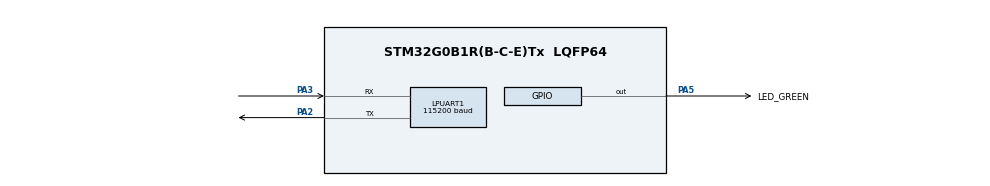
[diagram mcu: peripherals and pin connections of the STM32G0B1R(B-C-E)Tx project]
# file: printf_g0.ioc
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LPUART1.BaudRate=115200
LPUART1.WordLength=UART_WORDLENGTH_8B
Mcu.Family=STM32G0
Mcu.Name=STM32G0B1R(B-C-E)Tx
Mcu.Package=LQFP64
PA13.GPIO_Label=TMS
PA13.Signal=SYS_SWDIO
PA14-BOOT0.GPIO_Label=TCK
PA14-BOOT0.Signal=SYS_SWCLK
PA2.Mode=Asynchronous
PA2.Signal=LPUART1_TX
PA3.Mode=Asynchronous
PA3.Signal=LPUART1_RX
PA5.GPIO_Label=LED_GREEN
PA5.GPIO_Speed=GPIO_SPEED_FREQ_HIGH
PA5.Signal=GPIO_Output
PC13.Signal=SYS_WKUP2
PC14-OSC32_IN\ (PC14).Signal=RCC_OSC32_IN
PC15-OSC32_OUT\ (PC15).Signal=RCC_OSC32_OUT
PF0-OSC_IN\ (PF0).GPIO_Label=MCO
PF0-OSC_IN\ (PF0).Signal=RCC_OSC_IN
ProjectManager.HeapSize=0x200
ProjectManager.StackSize=0x400
ProjectManager.TargetToolchain=STM32CubeIDE
RCC.ADCFreq_Value=64000000
RCC.AHBFreq_Value=64000000
RCC.CortexFreq_Value=64000000
RCC.EXTERNAL_CLOCK_VALUE=12288000
RCC.HCLKFreq_Value=64000000
RCC.HSE_VALUE=8000000
RCC.HSI48_VALUE=48000000
RCC.HSI_VALUE=16000000
RCC.LSE_VALUE=32768
RCC.SYSCLKFreq_VALUE=64000000
RCC.SYSCLKSource=RCC_SYSCLKSOURCE_PLLCLK
RCC.USBFreq_Value=48000000
RCC.VCOOutputFreq_Value=128000000
VP_SYS_VS_DBSignals.Mode=DisableDeadBatterySignals
board=NUCLEO-G0B1RE

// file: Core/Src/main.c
/* USER CODE BEGIN Header */
/**
  ******************************************************************************
  * @file           : main.c
  * @brief          : Main program body
  ******************************************************************************
  * @attention
  *
  * Copyright (c) 2024 STMicroelectronics.
  * All rights reserved.
  *
  * This software is licensed under terms that can be found in the LICENSE file
  * in the root directory of this software component.
  * If no LICENSE file comes with this software, it is provided AS-IS.
  *
  ******************************************************************************
  */
/* USER CODE END Header */
#include "main.h"
#include<stdio.h>

UART_HandleTypeDef hlpuart1;

void SystemClock_Config(void);
static void MX_GPIO_Init(void);
static void MX_LPUART1_UART_Init(void);
/* USER CODE BEGIN PFP */
#define PUTCHAR_PROTOTYPE int fputc(int ch, FILE *f)
/* USER CODE END PFP */

int main(void)
{

  /* MCU Configuration--------------------------------------------------------*/

  /* Reset of all peripherals, Initializes the Flash interface and the Systick. */
  HAL_Init();

  /* Configure the system clock */
  SystemClock_Config();

  /* Initialize all configured peripherals */
  MX_GPIO_Init();
  MX_LPUART1_UART_Init();

  /* Infinite loop */
  while (1)
  {

    /* USER CODE BEGIN 3 */

LL_GPIO_TogglePin(GPIOA, LL_GPIO_PIN_5);
LL_mDelay(1000);
     // printf("** Hello World ** \n\r");
      //HAL_Delay(1000);
  }
  /* USER CODE END 3 */
}

void SystemClock_Config(void)
{
  LL_FLASH_SetLatency(LL_FLASH_LATENCY_2);
  while(LL_FLASH_GetLatency() != LL_FLASH_LATENCY_2)
  {
  }

  /* HSI configuration and activation */
  LL_RCC_HSI_Enable();
  while(LL_RCC_HSI_IsReady() != 1)
  {
  }

  /* Main PLL configuration and activation */
  LL_RCC_PLL_ConfigDomain_SYS(LL_RCC_PLLSOURCE_HSI, LL_RCC_PLLM_DIV_1, 8, LL_RCC_PLLR_DIV_2);
  LL_RCC_PLL_Enable();
  LL_RCC_PLL_EnableDomain_SYS();
  while(LL_RCC_PLL_IsReady() != 1)
  {
  }

  /* Set AHB prescaler*/
  LL_RCC_SetAHBPrescaler(LL_RCC_SYSCLK_DIV_1);

  /* Sysclk activation on the main PLL */
  LL_RCC_SetSysClkSource(LL_RCC_SYS_CLKSOURCE_PLL);
  while(LL_RCC_GetSysClkSource() != LL_RCC_SYS_CLKSOURCE_STATUS_PLL)
  {
  }

  /* Set APB1 prescaler*/
  LL_RCC_SetAPB1Prescaler(LL_RCC_APB1_DIV_1);
  /* Update CMSIS variable (which can be updated also through SystemCoreClockUpdate function) */
  LL_SetSystemCoreClock(64000000);

   /* Update the time base */
  if (HAL_InitTick (TICK_INT_PRIORITY) != HAL_OK)
  {
    Error_Handler();
  }
}

static void MX_LPUART1_UART_Init(void)
{

  hlpuart1.Instance = LPUART1;
  hlpuart1.Init.BaudRate = 115200;
  hlpuart1.Init.WordLength = UART_WORDLENGTH_8B;
  hlpuart1.Init.StopBits = UART_STOPBITS_1;
  hlpuart1.Init.Parity = UART_PARITY_NONE;
  hlpuart1.Init.Mode = UART_MODE_TX_RX;
  hlpuart1.Init.HwFlowCtl = UART_HWCONTROL_NONE;
  hlpuart1.Init.OneBitSampling = UART_ONE_BIT_SAMPLE_DISABLE;
  hlpuart1.Init.ClockPrescaler = UART_PRESCALER_DIV1;
  hlpuart1.AdvancedInit.AdvFeatureInit = UART_ADVFEATURE_NO_INIT;
  hlpuart1.FifoMode = UART_FIFOMODE_DISABLE;
  if (HAL_UART_Init(&hlpuart1) != HAL_OK)
  {
    Error_Handler();
  }
  if (HAL_UARTEx_SetTxFifoThreshold(&hlpuart1, UART_TXFIFO_THRESHOLD_1_8) != HAL_OK)
  {
    Error_Handler();
  }
  if (HAL_UARTEx_SetRxFifoThreshold(&hlpuart1, UART_RXFIFO_THRESHOLD_1_8) != HAL_OK)
  {
    Error_Handler();
  }
  if (HAL_UARTEx_DisableFifoMode(&hlpuart1) != HAL_OK)
  {
    Error_Handler();
  }

}

static void MX_GPIO_Init(void)
{
  LL_GPIO_InitTypeDef GPIO_InitStruct = {0};

  /* GPIO Ports Clock Enable */
  LL_IOP_GRP1_EnableClock(LL_IOP_GRP1_PERIPH_GPIOC);
  LL_IOP_GRP1_EnableClock(LL_IOP_GRP1_PERIPH_GPIOF);
  LL_IOP_GRP1_EnableClock(LL_IOP_GRP1_PERIPH_GPIOA);

  /**/
  LL_GPIO_ResetOutputPin(LED_GREEN_GPIO_Port, LED_GREEN_Pin);

  /**/
  GPIO_InitStruct.Pin = LED_GREEN_Pin;
  GPIO_InitStruct.Mode = LL_GPIO_MODE_OUTPUT;
  GPIO_InitStruct.Speed = LL_GPIO_SPEED_FREQ_HIGH;
  GPIO_InitStruct.OutputType = LL_GPIO_OUTPUT_PUSHPULL;
  GPIO_InitStruct.Pull = LL_GPIO_PULL_NO;
  LL_GPIO_Init(LED_GREEN_GPIO_Port, &GPIO_InitStruct);

}

/* USER CODE BEGIN 4 */
PUTCHAR_PROTOTYPE
     {
          HAL_UART_Transmit(&hlpuart1, (uint8_t *)&ch, 1, 0xFFFF);
          return ch;
      }

/* USER CODE END 4 */

void Error_Handler(void)
{
  __disable_irq();
  while (1)
  {
  }
}
